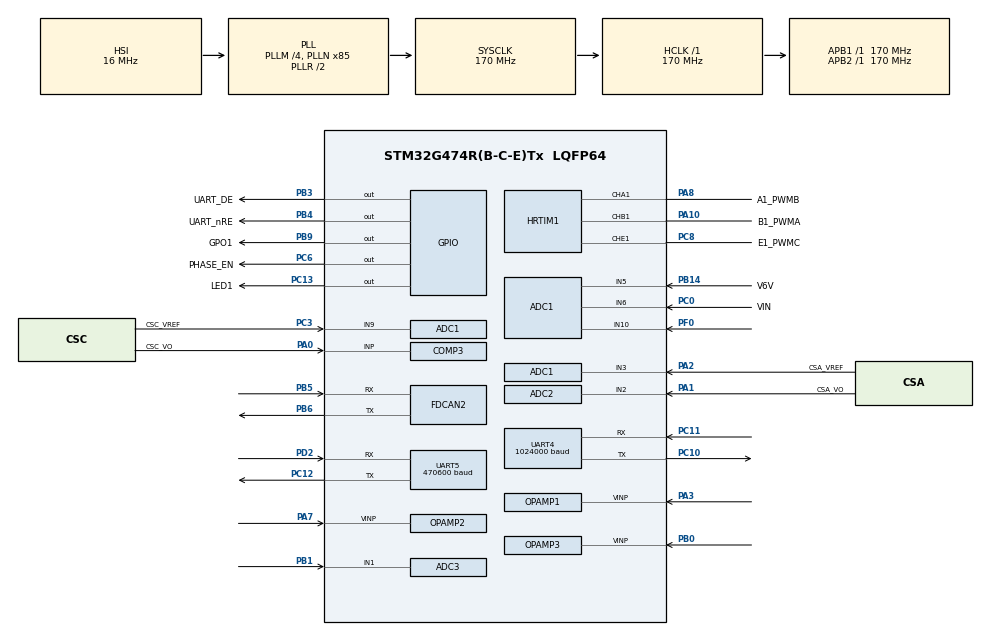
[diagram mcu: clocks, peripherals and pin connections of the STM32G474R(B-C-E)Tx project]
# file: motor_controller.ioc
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ADC1.Channel-0\#ChannelRegularConversion=ADC_CHANNEL_3
ADC1.Channel-1\#ChannelRegularConversion=ADC_CHANNEL_9
ADC1.ClockPrescaler=ADC_CLOCK_SYNC_PCLK_DIV4
ADC1.ContinuousConvMode=DISABLE
ADC1.DMAContinuousRequests=ENABLE
ADC1.EOCSelection=ADC_EOC_SINGLE_CONV
ADC1.ExternalTrigConv=ADC_EXTERNALTRIG_HRTIM_TRG1
ADC1.NbrOfConversion=2
ADC1.NbrOfConversionFlag=1
ADC1.OffsetNumber-0\#ChannelRegularConversion=ADC_OFFSET_NONE
ADC1.OffsetNumber-1\#ChannelRegularConversion=ADC_OFFSET_NONE
ADC1.Overrun=ADC_OVR_DATA_OVERWRITTEN
ADC1.OversamplingMode=DISABLE
ADC1.Rank-0\#ChannelRegularConversion=1
ADC1.Rank-1\#ChannelRegularConversion=2
ADC1.SamplingTime-0\#ChannelRegularConversion=ADC_SAMPLETIME_2CYCLES_5
ADC1.SamplingTime-1\#ChannelRegularConversion=ADC_SAMPLETIME_2CYCLES_5
ADC1.master=1
ADC2.Channel-0\#ChannelRegularConversion=ADC_CHANNEL_2
ADC2.Channel-1\#ChannelRegularConversion=ADC_CHANNEL_1
ADC2.DMAContinuousRequests=ENABLE
ADC2.EnableInjectedConversion=ENABLE
ADC2.EnableInjectedOversampling=ENABLE
ADC2.ExternalTrigConv=ADC_EXTERNALTRIG_HRTIM_TRG1
ADC2.ExternalTrigInjecConv=ADC_EXTERNALTRIGINJEC_HRTIM_TRG2
ADC2.InjNumberOfConversion=1
ADC2.InjOversamplingRatio=ADC_OVERSAMPLING_RATIO_16
ADC2.InjOversamplingRightShift=ADC_RIGHTBITSHIFT_4
ADC2.InjectedChannel-2\#ChannelInjectedConversion=ADC_CHANNEL_1
ADC2.InjectedOffsetNumber-2\#ChannelInjectedConversion=ADC_OFFSET_NONE
ADC2.InjectedRank-2\#ChannelInjectedConversion=1
ADC2.InjectedSamplingTime-2\#ChannelInjectedConversion=ADC_SAMPLETIME_2CYCLES_5
ADC2.NbrOfConversion=2
ADC2.NbrOfConversionFlag=1
ADC2.OffsetNumber-0\#ChannelRegularConversion=ADC_OFFSET_NONE
ADC2.OffsetNumber-1\#ChannelRegularConversion=ADC_OFFSET_NONE
ADC2.Overrun=ADC_OVR_DATA_OVERWRITTEN
ADC2.OversamplingMode=DISABLE
ADC2.Rank-0\#ChannelRegularConversion=1
ADC2.Rank-1\#ChannelRegularConversion=2
ADC2.Rank1_Channel=ADC_CHANNEL_1
ADC2.SamplingTime-0\#ChannelRegularConversion=ADC_SAMPLETIME_2CYCLES_5
ADC2.SamplingTime-1\#ChannelRegularConversion=ADC_SAMPLETIME_2CYCLES_5
ADC3.Channel-0\#ChannelRegularConversion=ADC_CHANNEL_VOPAMP3_ADC3
ADC3.NbrOfConversionFlag=1
ADC3.OffsetNumber-0\#ChannelRegularConversion=ADC_OFFSET_NONE
ADC3.Rank-0\#ChannelRegularConversion=1
ADC3.SamplingTime-0\#ChannelRegularConversion=ADC_SAMPLETIME_2CYCLES_5
ADC3.master=1
DAC3.DAC_Channel-DAC_OUT2_Int=DAC_CHANNEL_2
Dma.ADC1.1.Direction=DMA_PERIPH_TO_MEMORY
Dma.ADC1.1.EventEnable=DISABLE
Dma.ADC1.1.Instance=DMA1_Channel2
Dma.ADC1.1.MemDataAlignment=DMA_MDATAALIGN_HALFWORD
Dma.ADC1.1.MemInc=DMA_MINC_ENABLE
Dma.ADC1.1.Mode=DMA_CIRCULAR
Dma.ADC1.1.PeriphDataAlignment=DMA_PDATAALIGN_HALFWORD
Dma.ADC1.1.PeriphInc=DMA_PINC_DISABLE
Dma.ADC1.1.Polarity=HAL_DMAMUX_REQ_GEN_RISING
Dma.ADC1.1.Priority=DMA_PRIORITY_HIGH
Dma.ADC1.1.RequestNumber=1
Dma.ADC1.1.SignalID=NONE
Dma.ADC1.1.SyncEnable=DISABLE
Dma.ADC1.1.SyncPolarity=HAL_DMAMUX_SYNC_NO_EVENT
Dma.ADC1.1.SyncRequestNumber=1
Dma.ADC1.1.SyncSignalID=NONE
Dma.ADC2.0.Direction=DMA_PERIPH_TO_MEMORY
Dma.ADC2.0.EventEnable=DISABLE
Dma.ADC2.0.Instance=DMA1_Channel1
Dma.ADC2.0.MemDataAlignment=DMA_MDATAALIGN_HALFWORD
Dma.ADC2.0.MemInc=DMA_MINC_ENABLE
Dma.ADC2.0.Mode=DMA_CIRCULAR
Dma.ADC2.0.PeriphDataAlignment=DMA_PDATAALIGN_HALFWORD
Dma.ADC2.0.PeriphInc=DMA_PINC_DISABLE
Dma.ADC2.0.Polarity=HAL_DMAMUX_REQ_GEN_RISING
Dma.ADC2.0.Priority=DMA_PRIORITY_HIGH
Dma.ADC2.0.RequestNumber=1
Dma.ADC2.0.SignalID=NONE
Dma.ADC2.0.SyncEnable=DISABLE
Dma.ADC2.0.SyncPolarity=HAL_DMAMUX_SYNC_NO_EVENT
Dma.ADC2.0.SyncRequestNumber=1
Dma.ADC2.0.SyncSignalID=NONE
Dma.Request0=ADC2
Dma.Request1=ADC1
Dma.Request2=UART5_RX
Dma.UART5_RX.2.Direction=DMA_PERIPH_TO_MEMORY
Dma.UART5_RX.2.EventEnable=DISABLE
Dma.UART5_RX.2.Instance=DMA1_Channel3
Dma.UART5_RX.2.MemDataAlignment=DMA_MDATAALIGN_BYTE
Dma.UART5_RX.2.MemInc=DMA_MINC_ENABLE
Dma.UART5_RX.2.Mode=DMA_CIRCULAR
Dma.UART5_RX.2.PeriphDataAlignment=DMA_PDATAALIGN_BYTE
Dma.UART5_RX.2.PeriphInc=DMA_PINC_DISABLE
Dma.UART5_RX.2.Polarity=HAL_DMAMUX_REQ_GEN_RISING
Dma.UART5_RX.2.Priority=DMA_PRIORITY_LOW
Dma.UART5_RX.2.RequestNumber=1
Dma.UART5_RX.2.SignalID=NONE
Dma.UART5_RX.2.SyncEnable=DISABLE
Dma.UART5_RX.2.SyncPolarity=HAL_DMAMUX_SYNC_NO_EVENT
Dma.UART5_RX.2.SyncRequestNumber=1
Dma.UART5_RX.2.SyncSignalID=NONE
FDCAN2.CalculateBaudRateNominal=500000
FDCAN2.CalculateTimeBitNominal=2000
FDCAN2.CalculateTimeQuantumNominal=117.64705882352942
FDCAN2.ExtFiltersNbr=0
FDCAN2.NominalPrescaler=20
FDCAN2.NominalSyncJumpWidth=3
FDCAN2.NominalTimeSeg1=13
FDCAN2.NominalTimeSeg2=3
FDCAN2.StdFiltersNbr=0
HRTIM1.ADCTrigger1_Source1=HRTIM_ADCTRIGGEREVENT13_MASTER_CMP1
HRTIM1.ADCTrigger2_Source1=HRTIM_ADCTRIGGEREVENT24_MASTER_PERIOD
HRTIM1.ADCTrigger_Id1=HRTIM_ADCTRIGGER_1
HRTIM1.ADCTrigger_Id2=HRTIM_ADCTRIGGER_2
HRTIM1.CompareUnit1-MasterTimer=HRTIM_COMPAREUNIT_1
HRTIM1.CompareUnit1-Output_TA1=HRTIM_COMPAREUNIT_1
HRTIM1.CompareUnit1-Output_TB1=HRTIM_COMPAREUNIT_1
HRTIM1.CompareUnit1-Output_TE1=HRTIM_COMPAREUNIT_1
HRTIM1.CompareUnit2-Output_TE1=__NULL
HRTIM1.CompareUnit3-Output_TE1=__NULL
HRTIM1.CompareValue1-Output_TA1=10000
HRTIM1.CompareValue1-Output_TB1=10000
HRTIM1.CompareValue1-Output_TE1=10000
HRTIM1.Event_EEV1=__NULL
HRTIM1.InterleavedMode-MasterTimer=HRTIM_INTERLEAVED_MODE_DUAL
HRTIM1.InterruptRequests1_Master=HRTIM_MASTER_IT_MUPD
HRTIM1.ModeTimeBase-Output_TA1=HRTIM_MODE_CONTINUOUS
HRTIM1.ModeTimeBase-Output_TB1=HRTIM_MODE_CONTINUOUS
HRTIM1.ModeTimeBase-Output_TE1=HRTIM_MODE_CONTINUOUS
HRTIM1.NumberADCTriggerSource1=1
HRTIM1.NumberADCTriggerSource2=1
HRTIM1.NumberInterruptRequests_Master-MasterTimer=1
HRTIM1.NumberResetSource1-Output_TA1=1
HRTIM1.NumberResetSource1-Output_TB1=1
HRTIM1.NumberResetSource1-Output_TE1=1
HRTIM1.NumberResetTrigger-Output_TA1=0
HRTIM1.NumberResetTrigger-Output_TB1=0
HRTIM1.NumberResetTrigger-Output_TE1=0
HRTIM1.NumberSetSource1-Output_TA1=1
HRTIM1.NumberSetSource1-Output_TB1=1
HRTIM1.NumberSetSource1-Output_TE1=1
HRTIM1.NumberUpdateTrigger-Output_TA1=0
HRTIM1.Periode_MASTER=HRTIM_PERIOD
HRTIM1.Periode_TA=HRTIM_PERIOD
HRTIM1.Periode_TB=HRTIM_PERIOD
HRTIM1.Periode_TE=HRTIM_PERIOD
HRTIM1.Polarity1-Output_TA1=HRTIM_OUTPUTPOLARITY_HIGH
HRTIM1.Polarity1-Output_TB1=HRTIM_OUTPUTPOLARITY_HIGH
HRTIM1.Polarity1-Output_TE1=HRTIM_OUTPUTPOLARITY_HIGH
HRTIM1.PreloadEnable-MasterTimer=HRTIM_PRELOAD_ENABLED
HRTIM1.PreloadEnable-Output_TA1=HRTIM_PRELOAD_ENABLED
HRTIM1.PreloadEnable-Output_TB1=HRTIM_PRELOAD_ENABLED
HRTIM1.PreloadEnable-Output_TE1=HRTIM_PRELOAD_ENABLED
HRTIM1.PrescalerRatio_MASTER=HRTIM_PRESCALERRATIO_MUL8
HRTIM1.PrescalerRatio_TA=HRTIM_PRESCALERRATIO_MUL16
HRTIM1.PrescalerRatio_TB=HRTIM_PRESCALERRATIO_MUL16
HRTIM1.PrescalerRatio_TE=HRTIM_PRESCALERRATIO_MUL16
HRTIM1.RepetitionUpdate-MasterTimer=HRTIM_UPDATEONREPETITION_ENABLED
HRTIM1.RepetitionUpdate-Output_TA1=HRTIM_UPDATEONREPETITION_ENABLED
HRTIM1.RepetitionUpdate-Output_TB1=HRTIM_UPDATEONREPETITION_ENABLED
HRTIM1.RepetitionUpdate-Output_TE1=HRTIM_UPDATEONREPETITION_ENABLED
HRTIM1.ResetOutput1_Source1-Output_TA1=HRTIM_OUTPUTRESET_TIMCMP1
HRTIM1.ResetOutput1_Source1-Output_TB1=HRTIM_OUTPUTRESET_TIMCMP1
HRTIM1.ResetOutput1_Source1-Output_TE1=HRTIM_OUTPUTRESET_TIMCMP1
HRTIM1.ResetUpdate-Output_TA1=HRTIM_TIMUPDATEONRESET_DISABLED
HRTIM1.ResetUpdate-Output_TB1=HRTIM_TIMUPDATEONRESET_DISABLED
HRTIM1.ResetUpdate-Output_TE1=HRTIM_TIMUPDATEONRESET_DISABLED
HRTIM1.SetOutput1_Source1-Output_TA1=HRTIM_OUTPUTSET_TIMCMP1
HRTIM1.SetOutput1_Source1-Output_TB1=HRTIM_OUTPUTSET_TIMCMP1
HRTIM1.SetOutput1_Source1-Output_TE1=HRTIM_OUTPUTSET_TIMCMP1
HRTIM1.UpDownMode-Output_TA1=HRTIM_TIMERUPDOWNMODE_UPDOWN
HRTIM1.UpDownMode-Output_TB1=HRTIM_TIMERUPDOWNMODE_UPDOWN
HRTIM1.UpDownMode-Output_TE1=HRTIM_TIMERUPDOWNMODE_UPDOWN
HRTIM1.postscaler1=0x1
Mcu.Family=STM32G4
Mcu.Name=STM32G474R(B-C-E)Tx
Mcu.Package=LQFP64
NVIC.FDCAN2_IT0_IRQn=true\:5\:0\:false\:false\:true\:true\:false\:false
NVIC.HRTIM1_Master_IRQn=true\:1\:0\:true\:false\:true\:true\:false\:true
NVIC.PriorityGroup=NVIC_PRIORITYGROUP_4
PA0.GPIO_Label=CSC_VO
PA0.Signal=SharedAnalog_PA0
PA1.GPIO_Label=CSA_VO
PA1.Mode=IN2-Single-Ended
PA1.Signal=ADC2_IN2
PA10.GPIO_Label=B1_PWMA
PA10.Mode=Output_TB1
PA10.Signal=HRTIM1_CHB1
PA13.Mode=Serial_Wire
PA13.Signal=SYS_JTMS-SWDIO
PA14.Mode=Serial_Wire
PA14.Signal=SYS_JTCK-SWCLK
PA2.GPIO_Label=CSA_VREF
PA2.Mode=IN3-Single-Ended
PA2.Signal=ADC1_IN3
PA3.Mode=Follower_Internally_Connected
PA3.Signal=OPAMP1_VINP
PA7.Mode=Follower_Internally_Connected
PA7.Signal=OPAMP2_VINP
PA8.GPIO_Label=A1_PWMB
PA8.Mode=Output_TA1
PA8.Signal=HRTIM1_CHA1
PB0.Mode=Follower_Internally_Connected
PB0.Signal=OPAMP3_VINP
PB1.Mode=IN1-Single-Ended
PB1.Signal=ADC3_IN1
PB14.GPIO_Label=V6V
PB14.Mode=IN5-Single-Ended
PB14.Signal=ADC1_IN5
PB3.GPIO_Label=UART_DE
PB3.Signal=GPIO_Output
PB4.GPIO_Label=UART_nRE
PB4.Signal=GPIO_Output
PB5.Mode=FDCAN_Activate
PB5.Signal=FDCAN2_RX
PB6.Mode=FDCAN_Activate
PB6.Signal=FDCAN2_TX
PB9.GPIO_Label=GPO1
PB9.Signal=GPIO_Output
PC0.GPIO_Label=VIN
PC0.Mode=IN6-Single-Ended
PC0.Signal=ADC1_IN6
PC10.Mode=Asynchronous
PC10.Signal=UART4_TX
PC11.Mode=Asynchronous
PC11.Signal=UART4_RX
PC12.Mode=Asynchronous
PC12.Signal=UART5_TX
PC13.GPIO_Label=LED1
PC13.Signal=GPIO_Output
PC3.GPIO_Label=CSC_VREF
PC3.Mode=IN9-Single-Ended
PC3.Signal=ADC1_IN9
PC6.GPIO_Label=PHASE_EN
PC6.Signal=GPIO_Output
PC8.GPIO_Label=E1_PWMC
PC8.Mode=Output_TE1
PC8.Signal=HRTIM1_CHE1
PD2.Mode=Asynchronous
PD2.Signal=UART5_RX
PF0-OSC_IN.Mode=IN10-Single-Ended
PF0-OSC_IN.Signal=ADC1_IN10
ProjectManager.HeapSize=0x200
ProjectManager.StackSize=0x400
ProjectManager.TargetToolchain=CMake
RCC.ADC12CLockSelection=RCC_ADC12CLKSOURCE_PLL
RCC.ADC12Freq_Value=85000000
RCC.ADC345Freq_Value=170000000
RCC.AHBFreq_Value=170000000
RCC.APB1Freq_Value=170000000
RCC.APB1TimFreq_Value=170000000
RCC.APB2Freq_Value=170000000
RCC.APB2TimFreq_Value=170000000
RCC.CK48CLockSelection=RCC_USBCLKSOURCE_HSI48
RCC.CortexFreq_Value=170000000
RCC.EXTERNAL_CLOCK_VALUE=12288000
RCC.HCLKFreq_Value=170000000
RCC.HSE_VALUE=8000000
RCC.HSI48_VALUE=48000000
RCC.HSI_VALUE=16000000
RCC.LSE_VALUE=32768
RCC.PLLM=RCC_PLLM_DIV4
RCC.PLLN=85
RCC.PLLP=RCC_PLLP_DIV4
RCC.SYSCLKFreq_VALUE=170000000
RCC.SYSCLKSource=RCC_SYSCLKSOURCE_PLLCLK
RCC.USBFreq_Value=48000000
RCC.VCOOutputFreq_Value=340000000
SH.SharedAnalog_PA0.0=COMP3_INP,INP
SH.SharedAnalog_PA0.1=ADC2_IN1,IN1-Single-Ended
UART4.BaudRate=1024000
UART4.Mode=MODE_TX
UART5.AutoBaudRateEnableParam=UART_ADVFEATURE_AUTOBAUDRATE_DISABLE
UART5.BaudRate=470600
UART5.Mode=MODE_TX_RX
VP_ADC1_OPAMP_INTERNAL1.Mode=IN-OPAMP1
VP_ADC2_OPAMP_INTERNAL2.Mode=IN-OPAMP2
VP_ADC3_OPAMP_INTERNAL3.Mode=IN-OPAMP3
VP_COMP3_VS_DAC3OUT1.Mode=INM_DAC3OUT1
VP_DAC3_VS_DACI1.Mode=DAC_OUT1_Int
VP_DAC3_VS_DACI2.Mode=DAC_OUT2_Int
VP_HRTIM1_VS_hrtimMasterTimerNoOutput.Mode=MasterTimer
VP_SYS_VS_DBSignals.Mode=DisableDeadBatterySignals
board=custom

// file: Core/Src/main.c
/* USER CODE BEGIN Header */
/**
  ******************************************************************************
  * @file           : main.c
  * @brief          : Main program body
  ******************************************************************************
  * @attention
  *
  * Copyright (c) 2026 STMicroelectronics.
  * All rights reserved.
  *
  * This software is licensed under terms that can be found in the LICENSE file
  * in the root directory of this software component.
  * If no LICENSE file comes with this software, it is provided AS-IS.
  *
  ******************************************************************************
  */
/* USER CODE END Header */
#include "main.h"
#include "adc.h"
#include "comp.h"
#include "dac.h"
#include "dma.h"
#include "fdcan.h"
#include "hrtim.h"
#include "opamp.h"
#include "usart.h"
#include "gpio.h"

/* USER CODE BEGIN Includes */
#include "app.h"
/* USER CODE END Includes */

void SystemClock_Config(void);

int main(void)
{

  /* MCU Configuration--------------------------------------------------------*/

  /* Reset of all peripherals, Initializes the Flash interface and the Systick. */
  HAL_Init();

  /* Configure the system clock */
  SystemClock_Config();

  /* Initialize all configured peripherals */
  MX_GPIO_Init();
  MX_DMA_Init();
  MX_ADC1_Init();
  MX_ADC2_Init();
  MX_ADC3_Init();
  MX_COMP3_Init();
  MX_DAC3_Init();
  MX_FDCAN2_Init();
  MX_HRTIM1_Init();
  MX_OPAMP1_Init();
  MX_OPAMP2_Init();
  MX_OPAMP3_Init();
  MX_UART4_Init();
  MX_UART5_Init();
  /* USER CODE BEGIN 2 */
  app_init();
  /* USER CODE END 2 */

  /* Infinite loop */
  /* USER CODE BEGIN WHILE */
  while (1)
  {
    app_step();
    /* USER CODE END WHILE */

    /* USER CODE BEGIN 3 */
    __WFI();   /* app_step() self-paces; sleep until the next interrupt */
  }
  /* USER CODE END 3 */
}

void SystemClock_Config(void)
{
  RCC_OscInitTypeDef RCC_OscInitStruct = {0};
  RCC_ClkInitTypeDef RCC_ClkInitStruct = {0};

  /** Configure the main internal regulator output voltage
  */
  HAL_PWREx_ControlVoltageScaling(PWR_REGULATOR_VOLTAGE_SCALE1_BOOST);

  /** Initializes the RCC Oscillators according to the specified parameters
  * in the RCC_OscInitTypeDef structure.
  */
  RCC_OscInitStruct.OscillatorType = RCC_OSCILLATORTYPE_HSI;
  RCC_OscInitStruct.HSIState = RCC_HSI_ON;
  RCC_OscInitStruct.HSICalibrationValue = RCC_HSICALIBRATION_DEFAULT;
  RCC_OscInitStruct.PLL.PLLState = RCC_PLL_ON;
  RCC_OscInitStruct.PLL.PLLSource = RCC_PLLSOURCE_HSI;
  RCC_OscInitStruct.PLL.PLLM = RCC_PLLM_DIV4;
  RCC_OscInitStruct.PLL.PLLN = 85;
  RCC_OscInitStruct.PLL.PLLP = RCC_PLLP_DIV4;
  RCC_OscInitStruct.PLL.PLLQ = RCC_PLLQ_DIV2;
  RCC_OscInitStruct.PLL.PLLR = RCC_PLLR_DIV2;
  if (HAL_RCC_OscConfig(&RCC_OscInitStruct) != HAL_OK)
  {
    Error_Handler();
  }

  /** Initializes the CPU, AHB and APB buses clocks
  */
  RCC_ClkInitStruct.ClockType = RCC_CLOCKTYPE_HCLK|RCC_CLOCKTYPE_SYSCLK
                              |RCC_CLOCKTYPE_PCLK1|RCC_CLOCKTYPE_PCLK2;
  RCC_ClkInitStruct.SYSCLKSource = RCC_SYSCLKSOURCE_PLLCLK;
  RCC_ClkInitStruct.AHBCLKDivider = RCC_SYSCLK_DIV1;
  RCC_ClkInitStruct.APB1CLKDivider = RCC_HCLK_DIV1;
  RCC_ClkInitStruct.APB2CLKDivider = RCC_HCLK_DIV1;

  if (HAL_RCC_ClockConfig(&RCC_ClkInitStruct, FLASH_LATENCY_4) != HAL_OK)
  {
    Error_Handler();
  }
}

void Error_Handler(void)
{
  __disable_irq();
  while (1)
  {
  }
}
